VERSION ""

NS_ :

BS_:

BU_: Tester

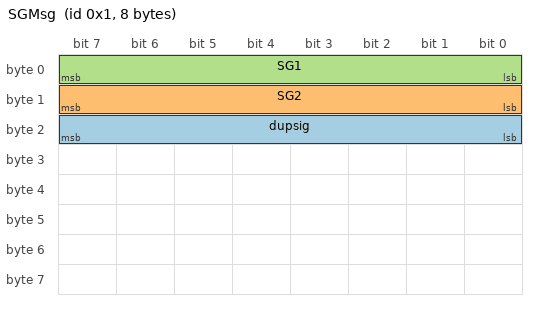
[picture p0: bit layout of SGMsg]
BO_ 1 SGMsg: 8 Vector__XXX
 SG_ dupsig : 16|8@1- (1,0) [0|0] "" Vector__XXX
 SG_ SG2 : 8|8@1- (1,0) [0|0] "" Vector__XXX
 SG_ SG1 : 0|8@1- (1,0) [0|0] "" Vector__XXX

BO_ 0 NormalMsg: 8 Vector__XXX
 SG_ Sig_2 : 8|8@1- (1,0) [0|0] "" Vector__XXX
 SG_ Sig_1 : 0|8@1- (1,0) [0|0] "" Vector__XXX

BA_DEF_  "BusType" STRING ;
BA_DEF_DEF_  "BusType" "CAN";

SIG_GROUP_ 1 Empty_Signal_Group 1 :;
